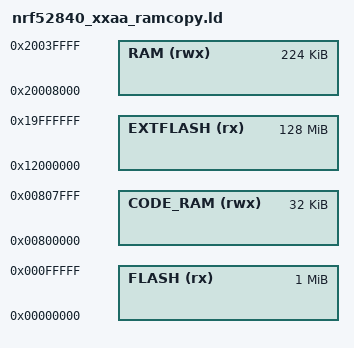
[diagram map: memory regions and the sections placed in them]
/* Linker script to configure memory regions. */

SEARCH_DIR(.)
GROUP(-lgcc -lc -lnosys)

MEMORY
{
  FLASH (rx) : ORIGIN = 0x00000000, LENGTH = 0x100000
  EXTFLASH (rx) : ORIGIN = 0x12000000, LENGTH = 0x8000000
  RAM (rwx) : ORIGIN = 0x20008000, LENGTH = 0x38000
  CODE_RAM (rwx) : ORIGIN = 0x800000, LENGTH = 0x8000
}


INCLUDE "nrf_common_ramcopy.ld"
